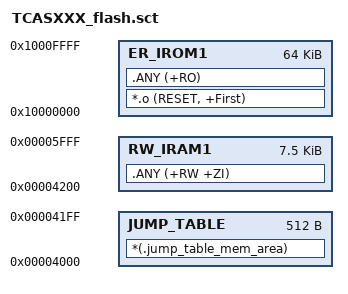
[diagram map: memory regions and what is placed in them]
; *************************************************************
; *** Scatter-Loading Description File generated by uVision ***
; *************************************************************

LR_IROM1 0x10000000 0x00010000  {    ; load region size_region
  ER_IROM1 0x10000000 0x00010000  {  ; load address = execution address
   *.o (RESET, +First)
   .ANY (+RO)
  }
  JUMP_TABLE 0x00004000 0x200 {
    *(.jump_table_mem_area)
  }
  RW_IRAM1 0x00004200 0x00001e00  {  ; RW data
   .ANY (+RW +ZI)
  }

}

